# PIC32MX470F512H register map
Registers are 32-bit, access not given, reset 0x0 unless marked. A register's access mark holds for its fields unless they carry their own. Offsets are from the block's base; [hi:lo] are bit positions; {n}, {i} and the like mark numbered series.

## PCACHE — PCACHE peripheral
Base 0xBF884000
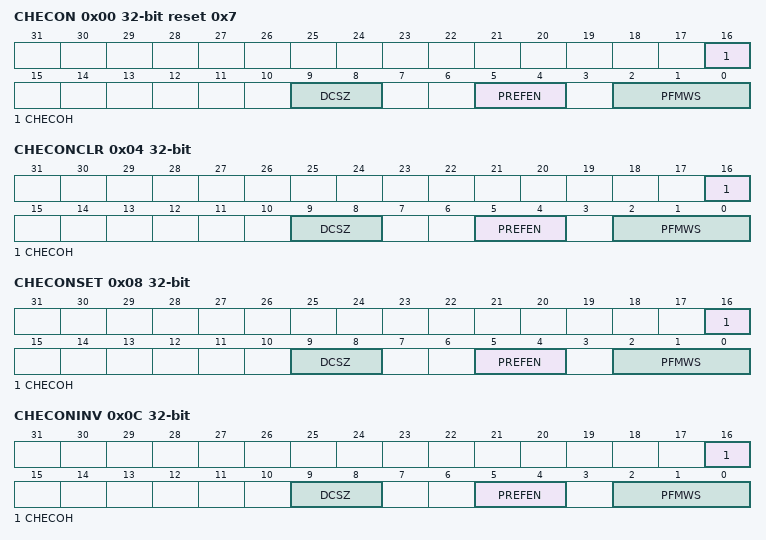
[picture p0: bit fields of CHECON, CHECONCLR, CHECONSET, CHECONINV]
0x00 CHECON reset 0x7
  [16] CHECOH, [9:8] DCSZ, [5:4] PREFEN, [2:0] PFMWS
0x04 CHECONCLR
  [16] CHECOH, [9:8] DCSZ, [5:4] PREFEN, [2:0] PFMWS
0x08 CHECONSET
  [16] CHECOH, [9:8] DCSZ, [5:4] PREFEN, [2:0] PFMWS
0x0C CHECONINV
  [16] CHECOH, [9:8] DCSZ, [5:4] PREFEN, [2:0] PFMWS
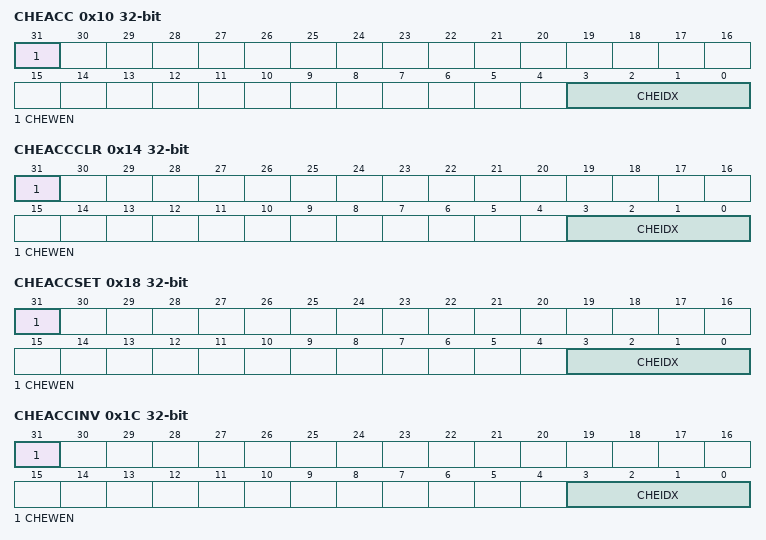
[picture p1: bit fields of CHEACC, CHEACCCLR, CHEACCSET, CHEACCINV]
0x10 CHEACC
  [31] CHEWEN, [3:0] CHEIDX
0x14 CHEACCCLR
  [31] CHEWEN, [3:0] CHEIDX
0x18 CHEACCSET
  [31] CHEWEN, [3:0] CHEIDX
0x1C CHEACCINV
  [31] CHEWEN, [3:0] CHEIDX
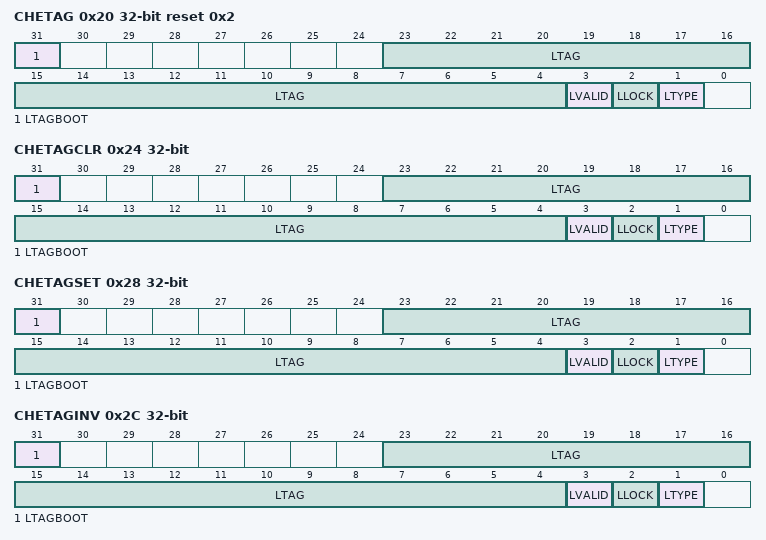
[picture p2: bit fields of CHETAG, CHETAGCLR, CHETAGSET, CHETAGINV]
0x20 CHETAG reset 0x2
  [31] LTAGBOOT, [23:4] LTAG, [3] LVALID, [2] LLOCK, [1] LTYPE
0x24 CHETAGCLR
  [31] LTAGBOOT, [23:4] LTAG, [3] LVALID, [2] LLOCK, [1] LTYPE
0x28 CHETAGSET
  [31] LTAGBOOT, [23:4] LTAG, [3] LVALID, [2] LLOCK, [1] LTYPE
0x2C CHETAGINV
  [31] LTAGBOOT, [23:4] LTAG, [3] LVALID, [2] LLOCK, [1] LTYPE
0x30 CHEMSK
  [15:5] LMASK
0x34 CHEMSKCLR
  [15:5] LMASK
0x38 CHEMSKSET
  [15:5] LMASK
0x3C CHEMSKINV
  [15:5] LMASK
{0x40+0x10*i} CHEW{i} (i=0..3)
0x80 CHELRU
  [24:0] CHELRU
0x90 CHEHIT
0xA0 CHEMIS
0xC0 CHEPFABT

## PORTB — PORTB peripheral
Base 0xBF886100
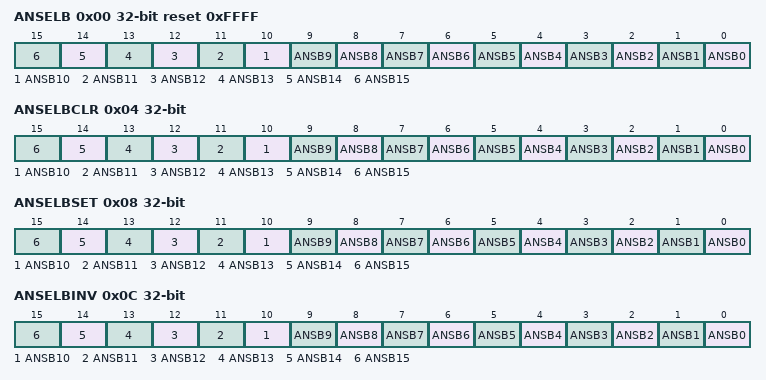
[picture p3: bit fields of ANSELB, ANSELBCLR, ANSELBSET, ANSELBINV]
0x00 ANSELB reset 0xFFFF
  [n] ANSB{n} (n=0..15)
0x04 ANSELBCLR
  [n] ANSB{n} (n=0..15)
0x08 ANSELBSET
  [n] ANSB{n} (n=0..15)
0x0C ANSELBINV
  [n] ANSB{n} (n=0..15)
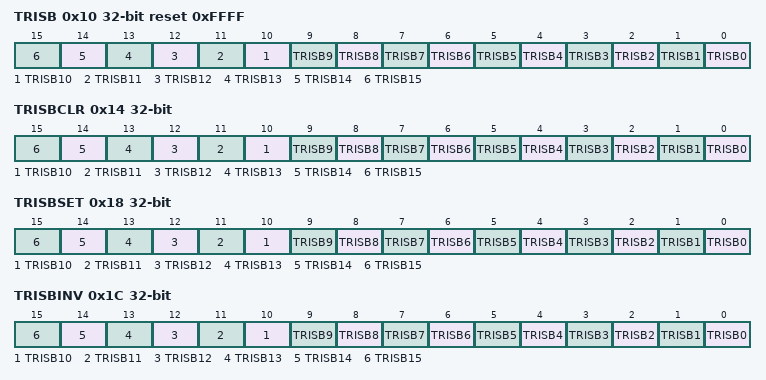
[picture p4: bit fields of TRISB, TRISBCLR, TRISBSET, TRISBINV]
0x10 TRISB reset 0xFFFF
  [n] TRISB{n} (n=0..15)
0x14 TRISBCLR
  [n] TRISB{n} (n=0..15)
0x18 TRISBSET
  [n] TRISB{n} (n=0..15)
0x1C TRISBINV
  [n] TRISB{n} (n=0..15)
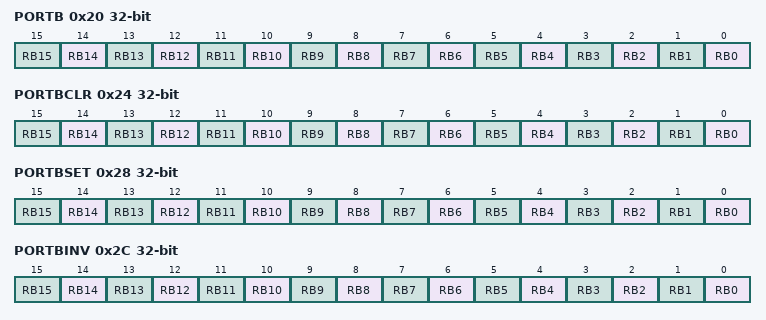
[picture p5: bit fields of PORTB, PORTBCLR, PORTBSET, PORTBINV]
0x20 PORTB
  [n] RB{n} (n=0..15)
0x24 PORTBCLR
  [n] RB{n} (n=0..15)
0x28 PORTBSET
  [n] RB{n} (n=0..15)
0x2C PORTBINV
  [n] RB{n} (n=0..15)
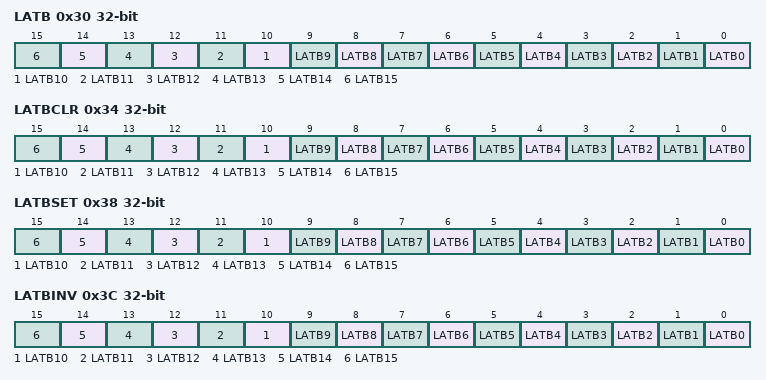
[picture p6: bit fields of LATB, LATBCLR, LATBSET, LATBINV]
0x30 LATB
  [n] LATB{n} (n=0..15)
0x34 LATBCLR
  [n] LATB{n} (n=0..15)
0x38 LATBSET
  [n] LATB{n} (n=0..15)
0x3C LATBINV
  [n] LATB{n} (n=0..15)
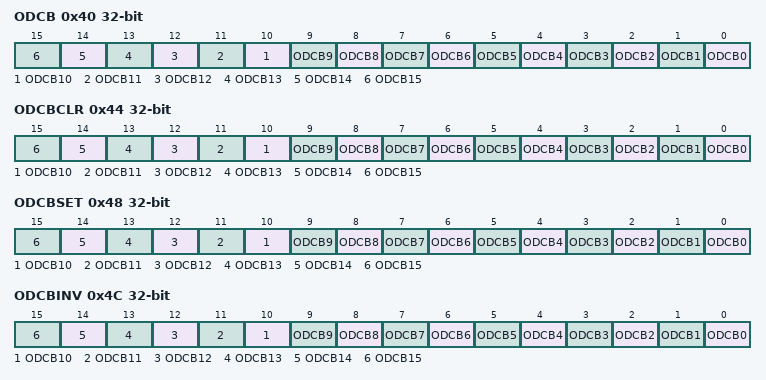
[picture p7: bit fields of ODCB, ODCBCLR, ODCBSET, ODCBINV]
0x40 ODCB
  [n] ODCB{n} (n=0..15)
0x44 ODCBCLR
  [n] ODCB{n} (n=0..15)
0x48 ODCBSET
  [n] ODCB{n} (n=0..15)
0x4C ODCBINV
  [n] ODCB{n} (n=0..15)
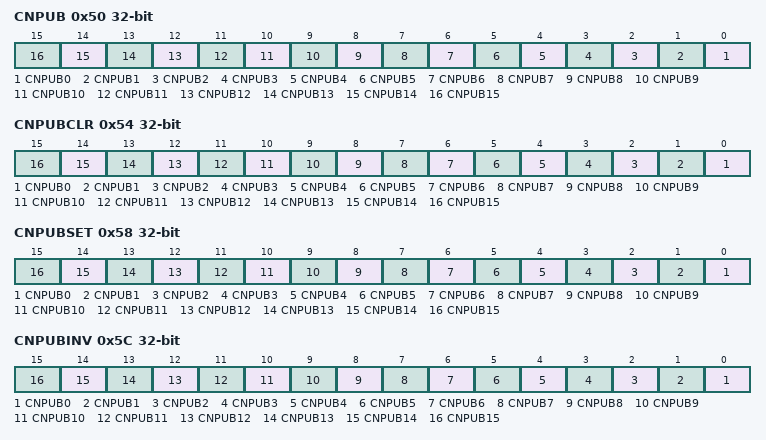
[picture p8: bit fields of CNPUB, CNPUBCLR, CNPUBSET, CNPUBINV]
0x50 CNPUB
  [n] CNPUB{n} (n=0..15)
0x54 CNPUBCLR
  [n] CNPUB{n} (n=0..15)
0x58 CNPUBSET
  [n] CNPUB{n} (n=0..15)
0x5C CNPUBINV
  [n] CNPUB{n} (n=0..15)
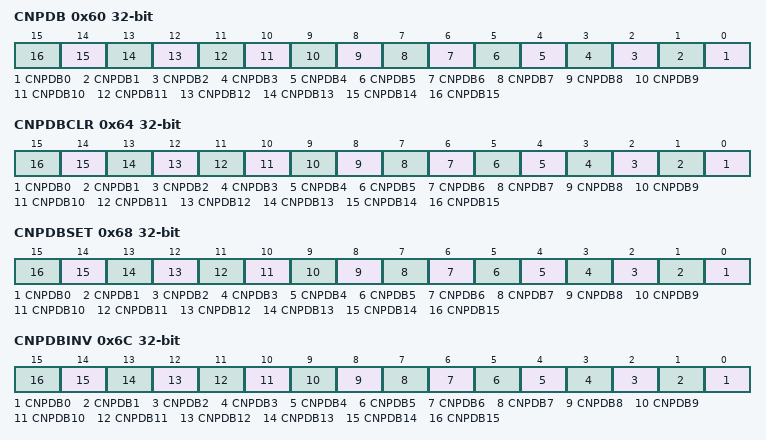
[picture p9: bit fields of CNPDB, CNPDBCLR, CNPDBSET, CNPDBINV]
0x60 CNPDB
  [n] CNPDB{n} (n=0..15)
0x64 CNPDBCLR
  [n] CNPDB{n} (n=0..15)
0x68 CNPDBSET
  [n] CNPDB{n} (n=0..15)
0x6C CNPDBINV
  [n] CNPDB{n} (n=0..15)
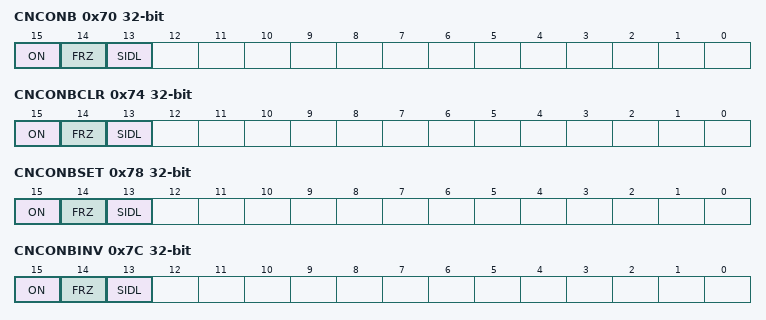
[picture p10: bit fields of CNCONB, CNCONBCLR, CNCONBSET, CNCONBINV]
0x70 CNCONB
  [15] ON, [14] FRZ, [13] SIDL
0x74 CNCONBCLR
  [15] ON, [14] FRZ, [13] SIDL
0x78 CNCONBSET
  [15] ON, [14] FRZ, [13] SIDL
0x7C CNCONBINV
  [15] ON, [14] FRZ, [13] SIDL
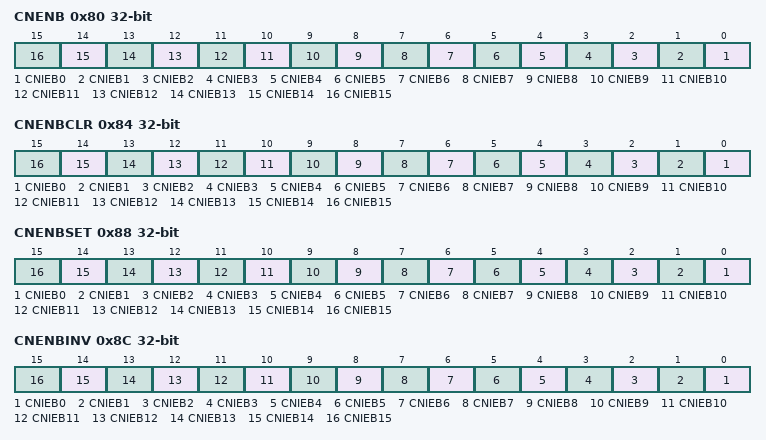
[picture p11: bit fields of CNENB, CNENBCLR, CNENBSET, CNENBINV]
0x80 CNENB
  [n] CNIEB{n} (n=0..15)
0x84 CNENBCLR
  [n] CNIEB{n} (n=0..15)
0x88 CNENBSET
  [n] CNIEB{n} (n=0..15)
0x8C CNENBINV
  [n] CNIEB{n} (n=0..15)
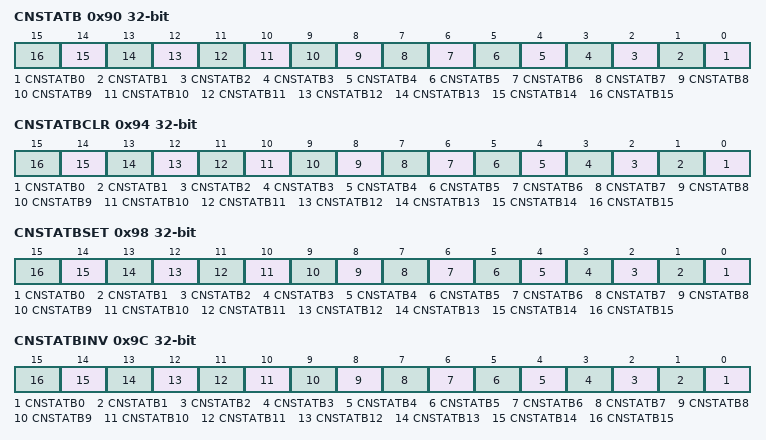
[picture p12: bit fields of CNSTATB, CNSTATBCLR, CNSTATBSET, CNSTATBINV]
0x90 CNSTATB
  [n] CNSTATB{n} (n=0..15)
0x94 CNSTATBCLR
  [n] CNSTATB{n} (n=0..15)
0x98 CNSTATBSET
  [n] CNSTATB{n} (n=0..15)
0x9C CNSTATBINV
  [n] CNSTATB{n} (n=0..15)

## PORTC — PORTC peripheral
Base 0xBF886200
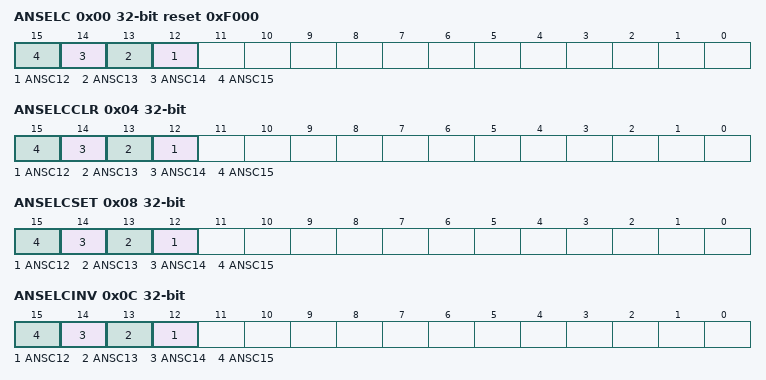
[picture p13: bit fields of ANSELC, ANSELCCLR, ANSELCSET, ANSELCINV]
0x00 ANSELC reset 0xF000
  [n] ANSC{n} (n=12..15)
0x04 ANSELCCLR
  [n] ANSC{n} (n=12..15)
0x08 ANSELCSET
  [n] ANSC{n} (n=12..15)
0x0C ANSELCINV
  [n] ANSC{n} (n=12..15)
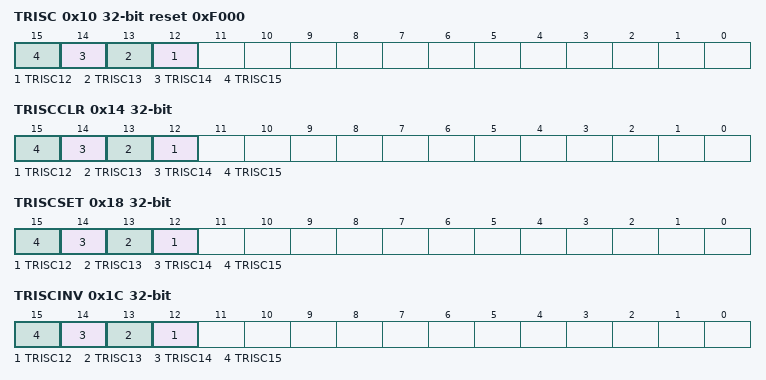
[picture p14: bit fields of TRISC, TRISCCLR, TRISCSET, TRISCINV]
0x10 TRISC reset 0xF000
  [n] TRISC{n} (n=12..15)
0x14 TRISCCLR
  [n] TRISC{n} (n=12..15)
0x18 TRISCSET
  [n] TRISC{n} (n=12..15)
0x1C TRISCINV
  [n] TRISC{n} (n=12..15)
0x20 PORTC
  [n] RC{n} (n=12..15)
0x24 PORTCCLR
  [n] RC{n} (n=12..15)
0x28 PORTCSET
  [n] RC{n} (n=12..15)
0x2C PORTCINV
  [n] RC{n} (n=12..15)
0x30 LATC
  [n] LATC{n} (n=12..15)
0x34 LATCCLR
  [n] LATC{n} (n=12..15)
0x38 LATCSET
  [n] LATC{n} (n=12..15)
0x3C LATCINV
  [n] LATC{n} (n=12..15)
0x40 ODCC
  [n] ODCC{n} (n=12..15)
0x44 ODCCCLR
  [n] ODCC{n} (n=12..15)
0x48 ODCCSET
  [n] ODCC{n} (n=12..15)
0x4C ODCCINV
  [n] ODCC{n} (n=12..15)
0x50 CNPUC
  [n] CNPUC{n} (n=12..15)
0x54 CNPUCCLR
  [n] CNPUC{n} (n=12..15)
0x58 CNPUCSET
  [n] CNPUC{n} (n=12..15)
0x5C CNPUCINV
  [n] CNPUC{n} (n=12..15)
0x60 CNPDC
  [n] CNPDC{n} (n=12..15)
0x64 CNPDCCLR
  [n] CNPDC{n} (n=12..15)
0x68 CNPDCSET
  [n] CNPDC{n} (n=12..15)
0x6C CNPDCINV
  [n] CNPDC{n} (n=12..15)
0x70 CNCONC
  [15] ON, [14] FRZ, [13] SIDL
0x74 CNCONCCLR
  [15] ON, [14] FRZ, [13] SIDL
0x78 CNCONCSET
  [15] ON, [14] FRZ, [13] SIDL
0x7C CNCONCINV
  [15] ON, [14] FRZ, [13] SIDL
0x80 CNENC
  [n] CNIEC{n} (n=12..15)
0x84 CNENCCLR
  [n] CNIEC{n} (n=12..15)
0x88 CNENCSET
  [n] CNIEC{n} (n=12..15)
0x8C CNENCINV
  [n] CNIEC{n} (n=12..15)
0x90 CNSTATC
  [n] CNSTATC{n} (n=12..15)
0x94 CNSTATCCLR
  [n] CNSTATC{n} (n=12..15)
0x98 CNSTATCSET
  [n] CNSTATC{n} (n=12..15)
0x9C CNSTATCINV
  [n] CNSTATC{n} (n=12..15)
